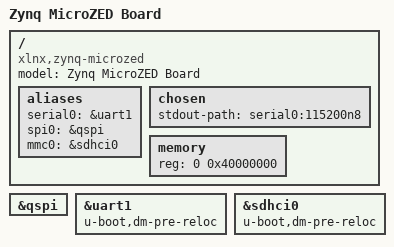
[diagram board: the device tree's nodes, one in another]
/*
 * Xilinx MicroZED board DTS
 *
 * Copyright (C) 2013 Xilinx, Inc.
 *
 * SPDX-License-Identifier:	GPL-2.0+
 * 
 * Modified: Oleg Dzhimiev <oleg@elphel.com>, Elphel Inc., 2016
 */
/dts-v1/;
#include "zynq-7000.dtsi"

/ {
	model = "Zynq MicroZED Board";
	compatible = "xlnx,zynq-microzed", "xlnx,zynq-7000";

	aliases {
		serial0 = &uart1;
		spi0 = &qspi;
                mmc0 = &sdhci0;
	};

        chosen {
                stdout-path = "serial0:115200n8";
        };
        
	memory {
		device_type = "memory";
		reg = <0 0x40000000>;
	};
};

&qspi {
	status = "okay";
};

&uart1 {
	u-boot,dm-pre-reloc;
	status = "okay";
};

&sdhci0 {
        u-boot,dm-pre-reloc;
        status = "okay";
};
